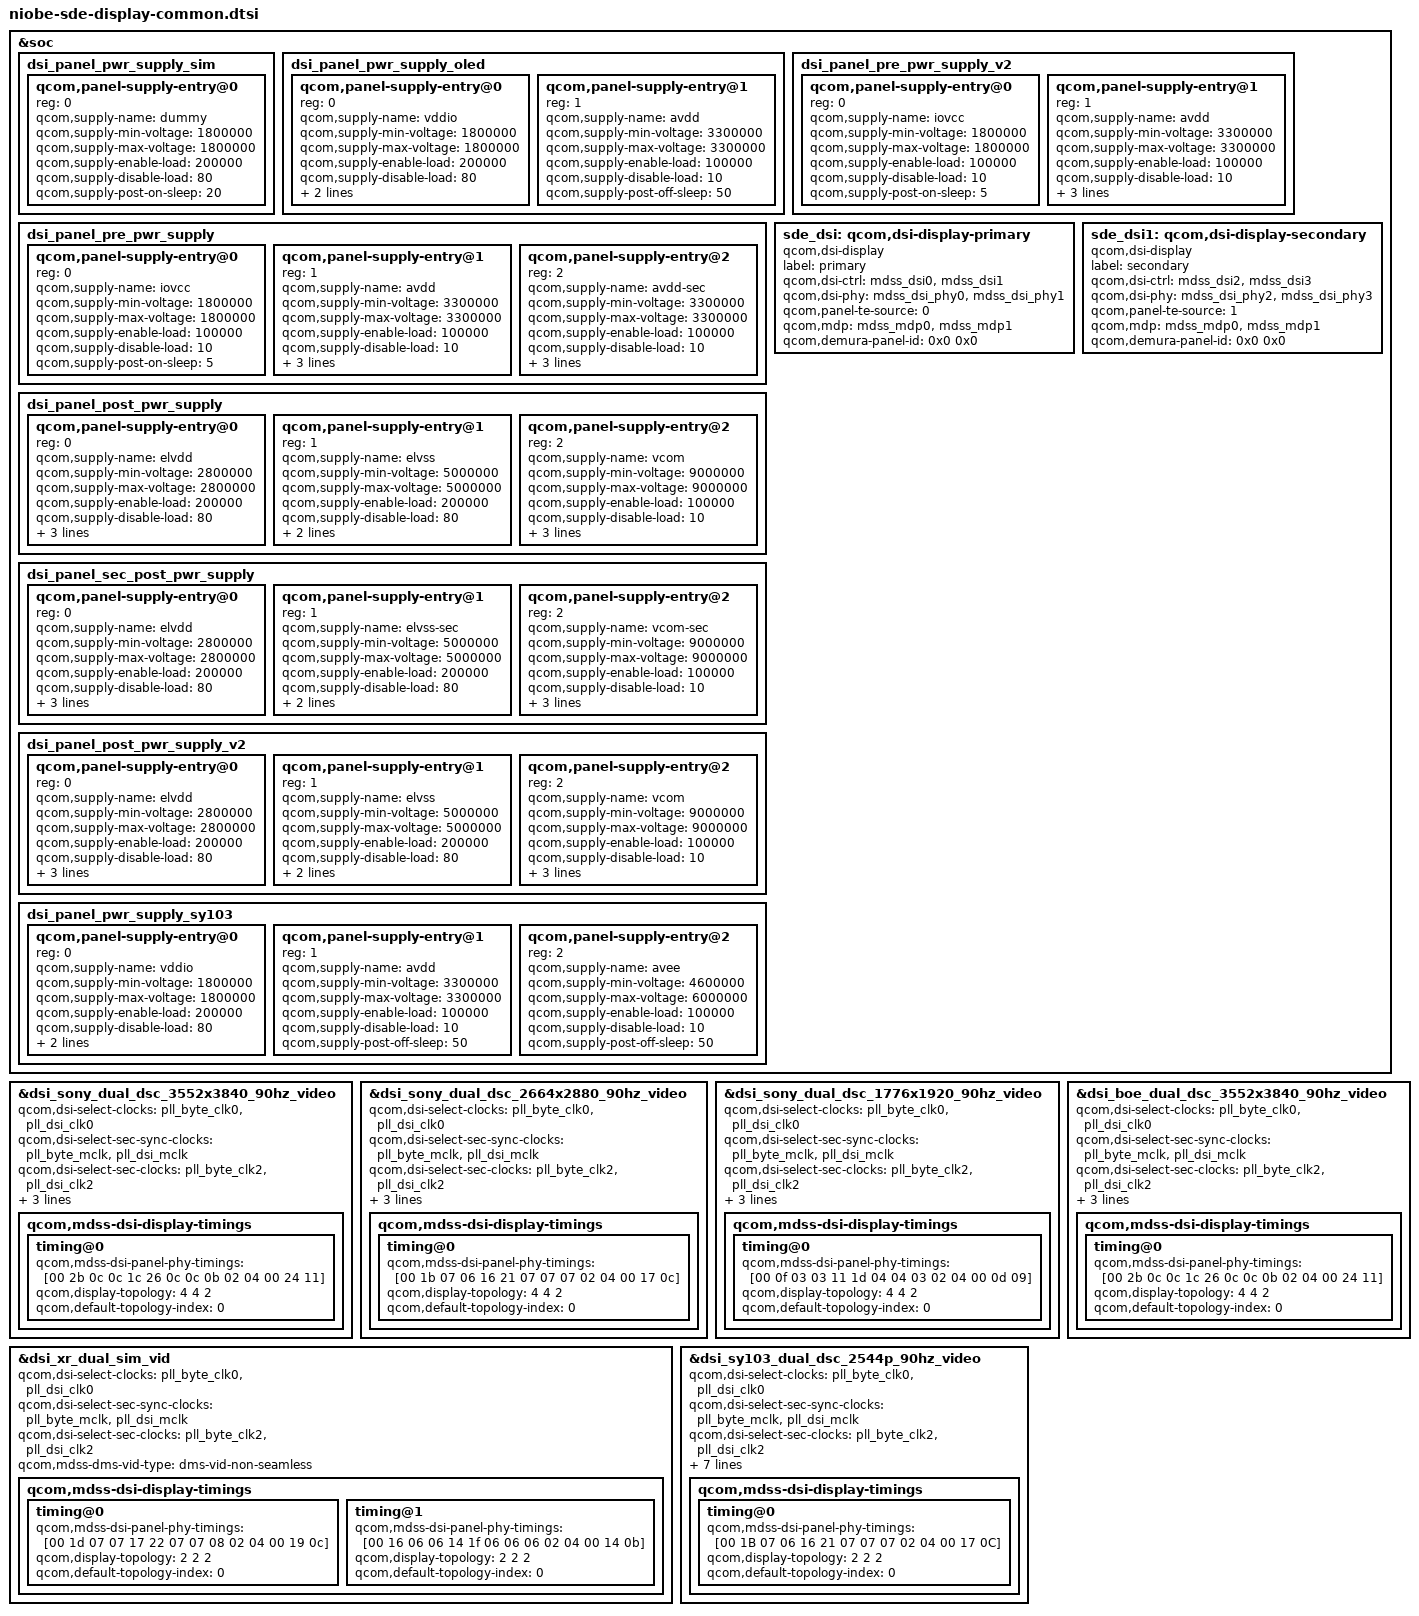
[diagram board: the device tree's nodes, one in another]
#include "dsi-panel-sony-dualmipi-dsc-3552x3840-video.dtsi"
#include "dsi-panel-sony-dualmipi-dsc-2664x2880-video.dtsi"
#include "dsi-panel-sony-dualmipi-dsc-1776x1920-video.dtsi"
#include "dsi-xr-panel-sim-dualmipi-video.dtsi"
#include "dsi-panel-sy103-dualmipi-dsc-2544p-90hz-video.dtsi"
#include "dsi-panel-boe-dualmipi-dsc-3552x3840-90hz-video.dtsi"

&soc {
	dsi_panel_pwr_supply_sim: dsi_panel_pwr_supply_sim {
		#address-cells = <1>;
		#size-cells = <0>;

		qcom,panel-supply-entry@0 {
			reg = <0>;
			qcom,supply-name = "dummy";
			qcom,supply-min-voltage = <1800000>;
			qcom,supply-max-voltage = <1800000>;
			qcom,supply-enable-load = <200000>;
			qcom,supply-disable-load = <80>;
			qcom,supply-post-on-sleep = <20>;
		};
	};

	dsi_panel_pwr_supply_oled: dsi_panel_pwr_supply_oled {
		#address-cells = <1>;
		#size-cells = <0>;

		qcom,panel-supply-entry@0 {
			reg = <0>;
			qcom,supply-name = "vddio";
			qcom,supply-min-voltage = <1800000>;
			qcom,supply-max-voltage = <1800000>;
			qcom,supply-enable-load = <200000>;
			qcom,supply-disable-load = <80>;
			qcom,supply-post-on-sleep = <10>;
			qcom,supply-post-off-sleep = <50>;
		};

		qcom,panel-supply-entry@1 {
			reg = <1>;
			qcom,supply-name = "avdd";
			qcom,supply-min-voltage = <3300000>;
			qcom,supply-max-voltage = <3300000>;
			qcom,supply-enable-load = <100000>;
			qcom,supply-disable-load = <10>;
			qcom,supply-post-off-sleep = <50>;
		};
	};

	dsi_panel_pre_pwr_supply: dsi_panel_pre_pwr_supply {
		#address-cells = <1>;
		#size-cells = <0>;

		qcom,panel-supply-entry@0 {
			reg = <0>;
			qcom,supply-name = "iovcc";
			qcom,supply-min-voltage = <1800000>;
			qcom,supply-max-voltage = <1800000>;
			qcom,supply-enable-load = <100000>;
			qcom,supply-disable-load = <10>;
			qcom,supply-post-on-sleep = <5>;
		};

		qcom,panel-supply-entry@1 {
			reg = <1>;
			qcom,supply-name = "avdd";
			qcom,supply-min-voltage = <3300000>;
			qcom,supply-max-voltage = <3300000>;
			qcom,supply-enable-load = <100000>;
			qcom,supply-disable-load = <10>;
			qcom,supply-post-on-sleep = <0>;
			qcom,supply-pre-off-sleep = <2>;
			qcom,supply-post-off-sleep = <2>;
		};

		qcom,panel-supply-entry@2 {
			reg = <2>;
			qcom,supply-name = "avdd-sec";
			qcom,supply-min-voltage = <3300000>;
			qcom,supply-max-voltage = <3300000>;
			qcom,supply-enable-load = <100000>;
			qcom,supply-disable-load = <10>;
			qcom,supply-post-on-sleep = <10>;
			qcom,supply-pre-off-sleep = <2>;
			qcom,supply-post-off-sleep = <2>;
		};
	};

	dsi_panel_post_pwr_supply: dsi_panel_post_pwr_supply {
		#address-cells = <1>;
		#size-cells = <0>;

		qcom,panel-supply-entry@0 {
			reg = <0>;
			qcom,supply-name = "elvdd";
			qcom,supply-min-voltage = <2800000>;
			qcom,supply-max-voltage = <2800000>;
			qcom,supply-enable-load = <200000>;
			qcom,supply-disable-load = <80>;
			qcom,supply-pre-on-sleep = <0>;
			qcom,supply-post-on-sleep = <20>;
			qcom,supply-post-off-sleep = <120>;
		};

		qcom,panel-supply-entry@1 {
			reg = <1>;
			qcom,supply-name = "elvss";
			qcom,supply-min-voltage = <5000000>;
			qcom,supply-max-voltage = <5000000>;
			qcom,supply-enable-load = <200000>;
			qcom,supply-disable-load = <80>;
			qcom,supply-post-on-sleep = <10>;
			qcom,supply-post-off-sleep = <5>;
		};

		qcom,panel-supply-entry@2 {
			reg = <2>;
			qcom,supply-name = "vcom";
			qcom,supply-min-voltage = <9000000>;
			qcom,supply-max-voltage = <9000000>;
			qcom,supply-enable-load = <100000>;
			qcom,supply-disable-load = <10>;
			qcom,supply-post-on-sleep = <5>;
			qcom,supply-pre-off-sleep = <2>;
			qcom,supply-post-off-sleep = <5>;
		};
	};

	dsi_panel_sec_post_pwr_supply: dsi_panel_sec_post_pwr_supply {
		#address-cells = <1>;
		#size-cells = <0>;

		qcom,panel-supply-entry@0 {
			reg = <0>;
			qcom,supply-name = "elvdd";
			qcom,supply-min-voltage = <2800000>;
			qcom,supply-max-voltage = <2800000>;
			qcom,supply-enable-load = <200000>;
			qcom,supply-disable-load = <80>;
			qcom,supply-pre-on-sleep = <0>;
			qcom,supply-post-on-sleep = <20>;
			qcom,supply-post-off-sleep = <120>;
		};

		qcom,panel-supply-entry@1 {
			reg = <1>;
			qcom,supply-name = "elvss-sec";
			qcom,supply-min-voltage = <5000000>;
			qcom,supply-max-voltage = <5000000>;
			qcom,supply-enable-load = <200000>;
			qcom,supply-disable-load = <80>;
			qcom,supply-post-on-sleep = <10>;
			qcom,supply-post-off-sleep = <5>;
		};

		qcom,panel-supply-entry@2 {
			reg = <2>;
			qcom,supply-name = "vcom-sec";
			qcom,supply-min-voltage = <9000000>;
			qcom,supply-max-voltage = <9000000>;
			qcom,supply-enable-load = <100000>;
			qcom,supply-disable-load = <10>;
			qcom,supply-post-on-sleep = <5>;
			qcom,supply-pre-off-sleep = <2>;
			qcom,supply-post-off-sleep = <5>;
		};
	};

	dsi_panel_pre_pwr_supply_v2: dsi_panel_pre_pwr_supply_v2 {
		#address-cells = <1>;
		#size-cells = <0>;

		qcom,panel-supply-entry@0 {
			reg = <0>;
			qcom,supply-name = "iovcc";
			qcom,supply-min-voltage = <1800000>;
			qcom,supply-max-voltage = <1800000>;
			qcom,supply-enable-load = <100000>;
			qcom,supply-disable-load = <10>;
			qcom,supply-post-on-sleep = <5>;
		};

		qcom,panel-supply-entry@1 {
			reg = <1>;
			qcom,supply-name = "avdd";
			qcom,supply-min-voltage = <3300000>;
			qcom,supply-max-voltage = <3300000>;
			qcom,supply-enable-load = <100000>;
			qcom,supply-disable-load = <10>;
			qcom,supply-post-on-sleep = <0>;
			qcom,supply-pre-off-sleep = <2>;
			qcom,supply-post-off-sleep = <2>;
		};
	};

	dsi_panel_post_pwr_supply_v2: dsi_panel_post_pwr_supply_v2 {
		#address-cells = <1>;
		#size-cells = <0>;

		qcom,panel-supply-entry@0 {
			reg = <0>;
			qcom,supply-name = "elvdd";
			qcom,supply-min-voltage = <2800000>;
			qcom,supply-max-voltage = <2800000>;
			qcom,supply-enable-load = <200000>;
			qcom,supply-disable-load = <80>;
			qcom,supply-pre-on-sleep = <0>;
			qcom,supply-post-on-sleep = <20>;
			qcom,supply-post-off-sleep = <120>;
		};

		qcom,panel-supply-entry@1 {
			reg = <1>;
			qcom,supply-name = "elvss";
			qcom,supply-min-voltage = <5000000>;
			qcom,supply-max-voltage = <5000000>;
			qcom,supply-enable-load = <200000>;
			qcom,supply-disable-load = <80>;
			qcom,supply-post-on-sleep = <10>;
			qcom,supply-post-off-sleep = <5>;
		};

		qcom,panel-supply-entry@2 {
			reg = <2>;
			qcom,supply-name = "vcom";
			qcom,supply-min-voltage = <9000000>;
			qcom,supply-max-voltage = <9000000>;
			qcom,supply-enable-load = <100000>;
			qcom,supply-disable-load = <10>;
			qcom,supply-post-on-sleep = <5>;
			qcom,supply-pre-off-sleep = <2>;
			qcom,supply-post-off-sleep = <5>;
		};
	};

	dsi_panel_pwr_supply_sy103: dsi_panel_pwr_supply_sy103 {
		#address-cells = <1>;
		#size-cells = <0>;

		qcom,panel-supply-entry@0 {
			reg = <0>;
			qcom,supply-name = "vddio";
			qcom,supply-min-voltage = <1800000>;
			qcom,supply-max-voltage = <1800000>;
			qcom,supply-enable-load = <200000>;
			qcom,supply-disable-load = <80>;
			qcom,supply-post-on-sleep = <10>;
			qcom,supply-post-off-sleep = <50>;
		};

		qcom,panel-supply-entry@1 {
			reg = <1>;
			qcom,supply-name = "avdd";
			qcom,supply-min-voltage = <3300000>;
			qcom,supply-max-voltage = <3300000>;
			qcom,supply-enable-load = <100000>;
			qcom,supply-disable-load = <10>;
			qcom,supply-post-off-sleep = <50>;
		};

		qcom,panel-supply-entry@2 {
			reg = <2>;
			qcom,supply-name = "avee";
			qcom,supply-min-voltage = <4600000>;
			qcom,supply-max-voltage = <6000000>;
			qcom,supply-enable-load = <100000>;
			qcom,supply-disable-load = <10>;
			qcom,supply-post-off-sleep = <50>;
		};
	};

	sde_dsi: qcom,dsi-display-primary {
		compatible = "qcom,dsi-display";
		label = "primary";

		qcom,dsi-ctrl = <&mdss_dsi0 &mdss_dsi1>;
		qcom,dsi-phy = <&mdss_dsi_phy0 &mdss_dsi_phy1>;

		qcom,panel-te-source = <0>;

		qcom,mdp = <&mdss_mdp0 &mdss_mdp1>;
		qcom,demura-panel-id = <0x0 0x0>;
	};

	sde_dsi1: qcom,dsi-display-secondary {
		compatible = "qcom,dsi-display";
		label = "secondary";

		qcom,dsi-ctrl = <&mdss_dsi2 &mdss_dsi3>;
		qcom,dsi-phy = <&mdss_dsi_phy2 &mdss_dsi_phy3>;

		qcom,panel-te-source = <1>;

		qcom,mdp = <&mdss_mdp0 &mdss_mdp1>;
		qcom,demura-panel-id = <0x0 0x0>;
	};
};

/* PHY TIMINGS REVISION YK with reduced margins*/
&dsi_sony_dual_dsc_3552x3840_90hz_video {
	qcom,dsi-select-clocks = "pll_byte_clk0", "pll_dsi_clk0";
	qcom,dsi-select-sec-sync-clocks = "pll_byte_mclk", "pll_dsi_mclk";
	qcom,dsi-select-sec-clocks = "pll_byte_clk2", "pll_dsi_clk2";

	qcom,mdss-dsi-panel-status-check-mode = "esd_sw_sim_success";
	qcom,esd-check-enabled;

	qcom,mdss-dsi-display-timings {
		timing@0 {
			qcom,mdss-dsi-panel-phy-timings = [00 2b 0c 0c 1c 26 0c
				0c 0b 02 04 00 24 11];
			qcom,display-topology = <4 4 2>;
			qcom,default-topology-index = <0>;
		};
	};
};

&dsi_sony_dual_dsc_2664x2880_90hz_video {
	qcom,dsi-select-clocks = "pll_byte_clk0", "pll_dsi_clk0";
	qcom,dsi-select-sec-sync-clocks = "pll_byte_mclk", "pll_dsi_mclk";
	qcom,dsi-select-sec-clocks = "pll_byte_clk2", "pll_dsi_clk2";

	qcom,mdss-dsi-panel-status-check-mode = "esd_sw_sim_success";
	qcom,esd-check-enabled;

	qcom,mdss-dsi-display-timings {
		timing@0 {
			qcom,mdss-dsi-panel-phy-timings = [00 1b 07 06 16 21 07
				07 07 02 04 00 17 0c];
			qcom,display-topology = <4 4 2>;
			qcom,default-topology-index = <0>;
		};
	};
};

&dsi_sony_dual_dsc_1776x1920_90hz_video {
	qcom,dsi-select-clocks = "pll_byte_clk0", "pll_dsi_clk0";
	qcom,dsi-select-sec-sync-clocks = "pll_byte_mclk", "pll_dsi_mclk";
	qcom,dsi-select-sec-clocks = "pll_byte_clk2", "pll_dsi_clk2";

	qcom,mdss-dsi-panel-status-check-mode = "esd_sw_sim_success";
	qcom,esd-check-enabled;

	qcom,mdss-dsi-display-timings {
		timing@0 {
			qcom,mdss-dsi-panel-phy-timings = [00 0f 03 03 11 1d 04
				04 03 02 04 00 0d 09];
			qcom,display-topology = <4 4 2>;
			qcom,default-topology-index = <0>;
		};
	};
};

&dsi_boe_dual_dsc_3552x3840_90hz_video {
	qcom,dsi-select-clocks = "pll_byte_clk0", "pll_dsi_clk0";
	qcom,dsi-select-sec-sync-clocks = "pll_byte_mclk", "pll_dsi_mclk";
	qcom,dsi-select-sec-clocks = "pll_byte_clk2", "pll_dsi_clk2";

	qcom,mdss-dsi-panel-status-check-mode = "esd_sw_sim_success";
	qcom,esd-check-enabled;

	qcom,mdss-dsi-display-timings {
		timing@0 {
			qcom,mdss-dsi-panel-phy-timings = [00 2b 0c 0c 1c 26 0c
				0c 0b 02 04 00 24 11];
			qcom,display-topology = <4 4 2>;
			qcom,default-topology-index = <0>;
		};
	};
};

&dsi_xr_dual_sim_vid {
	qcom,dsi-select-clocks = "pll_byte_clk0", "pll_dsi_clk0";
	qcom,dsi-select-sec-sync-clocks = "pll_byte_mclk", "pll_dsi_mclk";
	qcom,dsi-select-sec-clocks = "pll_byte_clk2", "pll_dsi_clk2";
	qcom,mdss-dms-vid-type = "dms-vid-non-seamless";

	qcom,mdss-dsi-display-timings {
		timing@0 {
			qcom,mdss-dsi-panel-phy-timings = [00 1d 07 07 17 22 07
				07 08 02 04 00 19 0c];
			qcom,display-topology = <2 2 2>;
			qcom,default-topology-index = <0>;
		};
		timing@1 {
			qcom,mdss-dsi-panel-phy-timings = [00 16 06 06 14 1f 06
				06 06 02 04 00 14 0b];
			qcom,display-topology = <2 2 2>;
			qcom,default-topology-index = <0>;
		};
	};
};

&dsi_sy103_dual_dsc_2544p_90hz_video {
	qcom,dsi-select-clocks = "pll_byte_clk0", "pll_dsi_clk0";
	qcom,dsi-select-sec-sync-clocks = "pll_byte_mclk", "pll_dsi_mclk";
	qcom,dsi-select-sec-clocks = "pll_byte_clk2", "pll_dsi_clk2";

	qcom,mdss-dsi-panel-status-check-mode = "esd_sw_sim_success";
	qcom,esd-check-enabled;

	qcom,dsi-supported-dfps-list = <90 75>;
	qcom,mdss-dsi-pan-enable-dynamic-fps;
	qcom,mdss-dsi-pan-fps-update = "dfps_immediate_porch_mode_vfp";

	qcom,mdss-dsi-display-timings {
		timing@0 {
			qcom,mdss-dsi-panel-phy-timings = [00 1B 07 06 16 21 07
				07 07 02 04 00 17 0C];
			qcom,display-topology = <2 2 2>;
			qcom,default-topology-index = <0>;
		};
	};
};
